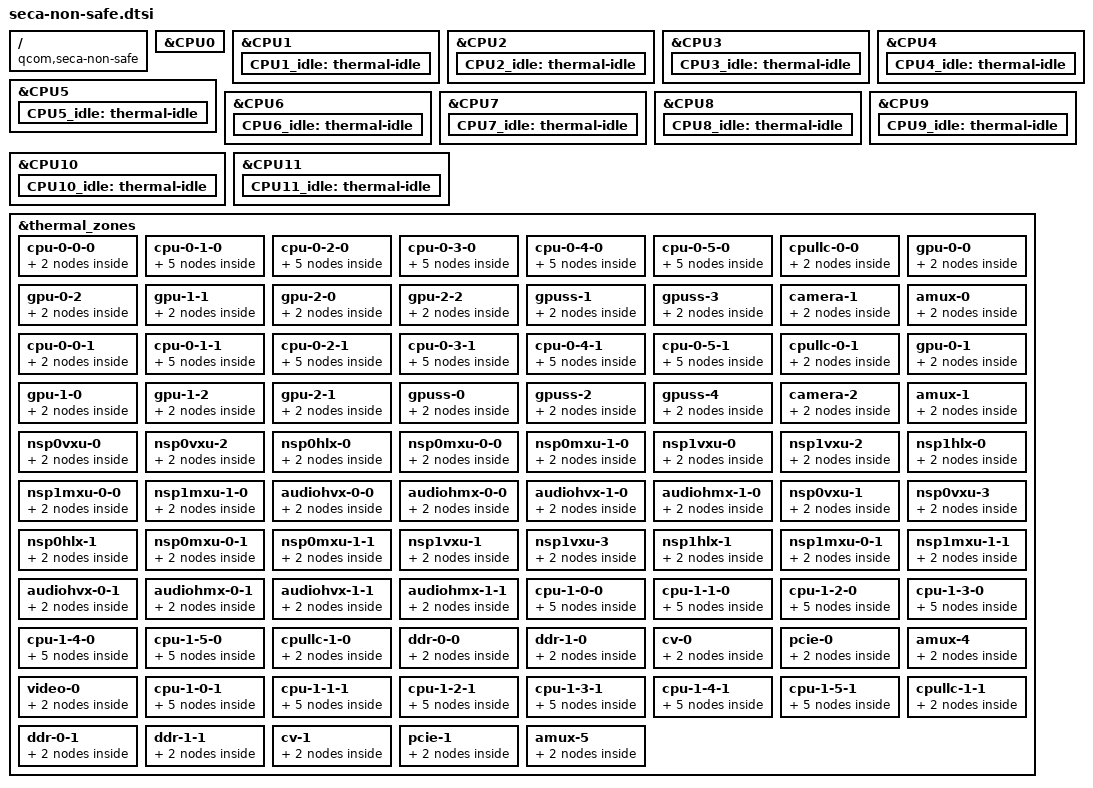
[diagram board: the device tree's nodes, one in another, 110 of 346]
// SPDX-License-Identifier: BSD-3-Clause
/*
 * Copyright (c) Qualcomm Technologies, Inc. and/or its subsidiaries.
 */

/ {
	compatible = "qcom,seca-non-safe","qcom,non-safe";
};

#include <dt-bindings/thermal/thermal.h>

&CPU0 {
	#cooling-cells = <2>;
};

&CPU1 {
	#cooling-cells = <2>;
	CPU1_idle: thermal-idle {
		#cooling-cells = <2>;
		duration-us = <800000>;
		exit-latency-us = <10000>;
	};
};

&CPU2 {
	#cooling-cells = <2>;
	CPU2_idle: thermal-idle {
		#cooling-cells = <2>;
		duration-us = <800000>;
		exit-latency-us = <10000>;
	};
};

&CPU3 {
	#cooling-cells = <2>;
	CPU3_idle: thermal-idle {
		#cooling-cells = <2>;
		duration-us = <800000>;
		exit-latency-us = <10000>;
	};
};

&CPU4 {
	#cooling-cells = <2>;
	CPU4_idle: thermal-idle {
		#cooling-cells = <2>;
		duration-us = <800000>;
		exit-latency-us = <10000>;
	};
};

&CPU5 {
	#cooling-cells = <2>;
	CPU5_idle: thermal-idle {
		#cooling-cells = <2>;
		duration-us = <800000>;
		exit-latency-us = <10000>;
	};
};

&CPU6 {
	#cooling-cells = <2>;
	CPU6_idle: thermal-idle {
		#cooling-cells = <2>;
		duration-us = <800000>;
		exit-latency-us = <10000>;
	};
};

&CPU7 {
	#cooling-cells = <2>;
	CPU7_idle: thermal-idle {
		#cooling-cells = <2>;
		duration-us = <800000>;
		exit-latency-us = <10000>;
	};
};

&CPU8 {
	#cooling-cells = <2>;
	CPU8_idle: thermal-idle {
		#cooling-cells = <2>;
		duration-us = <800000>;
		exit-latency-us = <10000>;
	};
};

&CPU9 {
	#cooling-cells = <2>;
	CPU9_idle: thermal-idle {
		#cooling-cells = <2>;
		duration-us = <800000>;
		exit-latency-us = <10000>;
	};
};

&CPU10 {
	#cooling-cells = <2>;
	CPU10_idle: thermal-idle {
		#cooling-cells = <2>;
		duration-us = <800000>;
		exit-latency-us = <10000>;
	};
};

&CPU11 {
	#cooling-cells = <2>;
	CPU11_idle: thermal-idle {
		#cooling-cells = <2>;
		duration-us = <800000>;
		exit-latency-us = <10000>;
	};
};


&thermal_zones {
	cpu-0-0-0 {
		trips {
			trip-point2 {
				temperature = <115000>;
				hysteresis = <3000>;
				type = "critical";
			};
		};
	};

	cpu-0-1-0 {
		trips {
			trip-point2 {
				temperature = <115000>;
				hysteresis = <3000>;
				type = "critical";
			};

			cpu1_alert0: trip-point1 {
				temperature = <114000>;
				hysteresis = <3000>;
			};
		};

		cooling-maps {
			map0 {
				trip = <&cpu1_alert0>;
				cooling-device = <&CPU1_idle 100 100>;
			};
		};
	};

	cpu-0-2-0 {
		trips {
			trip-point2 {
				temperature = <115000>;
				hysteresis = <3000>;
				type = "critical";
			};

			cpu2_alert0: trip-point1 {
				temperature = <114000>;
				hysteresis = <3000>;
			};
		};

		cooling-maps {
			map0 {
				trip = <&cpu2_alert0>;
				cooling-device = <&CPU2_idle 100 100>;
			};
		};
	};

	cpu-0-3-0 {
		trips {
			trip-point2 {
				temperature = <115000>;
				hysteresis = <3000>;
				type = "critical";
			};

			cpu3_alert0: trip-point1 {
				temperature = <114000>;
				hysteresis = <3000>;
			};
		};

		cooling-maps {
			map0 {
				trip = <&cpu3_alert0>;
				cooling-device = <&CPU3_idle 100 100>;
			};
		};
	};

	cpu-0-4-0 {
		trips {
			trip-point2 {
				temperature = <115000>;
				hysteresis = <3000>;
				type = "critical";
			};

			cpu4_alert0: trip-point1 {
				temperature = <114000>;
				hysteresis = <3000>;
			};
		};

		cooling-maps {
			map0 {
				trip = <&cpu4_alert0>;
				cooling-device = <&CPU4_idle 100 100>;
			};
		};
	};

	cpu-0-5-0 {
		trips {
			trip-point2 {
				temperature = <115000>;
				hysteresis = <3000>;
				type = "critical";
			};

			cpu5_alert0: trip-point1 {
				temperature = <114000>;
				hysteresis = <3000>;
			};
		};

		cooling-maps {
			map0 {
				trip = <&cpu5_alert0>;
				cooling-device = <&CPU5_idle 100 100>;
			};
		};
	};

	cpullc-0-0 {
		trips {
			trip-point2 {
				temperature = <115000>;
				hysteresis = <3000>;
				type = "critical";
			};
		};
	};

	gpu-0-0 {
		trips {
			trip-point2 {
				temperature = <115000>;
				hysteresis = <3000>;
				type = "critical";
			};
		};
	};

	gpu-0-2 {
		trips {
			trip-point2 {
				temperature = <115000>;
				hysteresis = <3000>;
				type = "critical";
			};
		};
	};

	gpu-1-1 {
		trips {
			trip-point2 {
				temperature = <115000>;
				hysteresis = <3000>;
				type = "critical";
			};
		};
	};

	gpu-2-0 {
		trips {
			trip-point2 {
				temperature = <115000>;
				hysteresis = <3000>;
				type = "critical";
			};
		};
	};

	gpu-2-2 {
		trips {
			trip-point2 {
				temperature = <115000>;
				hysteresis = <3000>;
				type = "critical";
			};
		};
	};

	gpuss-1 {
		trips {
			trip-point2 {
				temperature = <115000>;
				hysteresis = <3000>;
				type = "critical";
			};
		};
	};

	gpuss-3 {
		trips {
			trip-point2 {
				temperature = <115000>;
				hysteresis = <3000>;
				type = "critical";
			};
		};
	};

	camera-1 {
		trips {
			trip-point2 {
				temperature = <115000>;
				hysteresis = <3000>;
				type = "critical";
			};
		};
	};

	amux-0 {
		trips {
			trip-point2 {
				temperature = <115000>;
				hysteresis = <3000>;
				type = "critical";
			};
		};
	};

	cpu-0-0-1 {
		trips {
			trip-point2 {
				temperature = <115000>;
				hysteresis = <3000>;
				type = "critical";
			};
		};
	};

	cpu-0-1-1 {
		trips {
			trip-point2 {
				temperature = <115000>;
				hysteresis = <3000>;
				type = "critical";
			};

			cpu1_alert1: trip-point1 {
				temperature = <114000>;
				hysteresis = <3000>;
			};
		};

		cooling-maps {
			map0 {
				trip = <&cpu1_alert1>;
				cooling-device = <&CPU1_idle 100 100>;
			};
		};
	};

	cpu-0-2-1 {
		trips {
			trip-point2 {
				temperature = <115000>;
				hysteresis = <3000>;
				type = "critical";
			};

			cpu2_alert1: trip-point1 {
				temperature = <114000>;
				hysteresis = <3000>;
			};
		};

		cooling-maps {
			map0 {
				trip = <&cpu2_alert1>;
				cooling-device = <&CPU2_idle 100 100>;
			};
		};
	};

	cpu-0-3-1 {
		trips {
			trip-point2 {
				temperature = <115000>;
				hysteresis = <3000>;
				type = "critical";
			};

			cpu3_alert1: trip-point1 {
				temperature = <114000>;
				hysteresis = <3000>;
			};
		};

		cooling-maps {
			map0 {
				trip = <&cpu3_alert1>;
				cooling-device = <&CPU3_idle 100 100>;
			};
		};
	};

	cpu-0-4-1 {
		trips {
			trip-point2 {
				temperature = <115000>;
				hysteresis = <3000>;
				type = "critical";
			};

			cpu4_alert1: trip-point1 {
				temperature = <114000>;
				hysteresis = <3000>;
			};
		};

		cooling-maps {
			map0 {
				trip = <&cpu4_alert1>;
				cooling-device = <&CPU4_idle 100 100>;
			};
		};
	};

	cpu-0-5-1 {
		trips {
			trip-point2 {
				temperature = <115000>;
				hysteresis = <3000>;
				type = "critical";
			};

			cpu5_alert1: trip-point1 {
				temperature = <114000>;
				hysteresis = <3000>;
			};
		};

		cooling-maps {
			map0 {
				trip = <&cpu5_alert1>;
				cooling-device = <&CPU5_idle 100 100>;
			};
		};
	};

	cpullc-0-1 {
		trips {
			trip-point2 {
				temperature = <115000>;
				hysteresis = <3000>;
				type = "critical";
			};
		};
	};

	gpu-0-1 {
		trips {
			trip-point2 {
				temperature = <115000>;
				hysteresis = <3000>;
				type = "critical";
			};
		};
	};

	gpu-1-0 {
		trips {
			trip-point2 {
				temperature = <115000>;
				hysteresis = <3000>;
				type = "critical";
			};
		};
	};

	gpu-1-2 {
		trips {
			trip-point2 {
				temperature = <115000>;
				hysteresis = <3000>;
				type = "critical";
			};
		};
	};

	gpu-2-1 {
		trips {
			trip-point2 {
				temperature = <115000>;
				hysteresis = <3000>;
				type = "critical";
			};
		};
	};

	gpuss-0 {
		trips {
			trip-point2 {
				temperature = <115000>;
				hysteresis = <3000>;
				type = "critical";
			};
		};
	};

	gpuss-2 {
		trips {
			trip-point2 {
				temperature = <115000>;
				hysteresis = <3000>;
				type = "critical";
			};
		};
	};

	gpuss-4 {
		trips {
			trip-point2 {
				temperature = <115000>;
				hysteresis = <3000>;
				type = "critical";
			};
		};
	};

	camera-2 {
		trips {
			trip-point2 {
				temperature = <115000>;
				hysteresis = <3000>;
				type = "critical";
			};
		};
	};

	amux-1 {
		trips {
			trip-point2 {
				temperature = <115000>;
				hysteresis = <3000>;
				type = "critical";
			};
		};
	};

	nsp0vxu-0 {
		trips {
			trip-point2 {
				temperature = <115000>;
				hysteresis = <3000>;
				type = "critical";
			};
		};
	};

	nsp0vxu-2 {
		trips {
			trip-point2 {
				temperature = <115000>;
				hysteresis = <3000>;
				type = "critical";
			};
		};
	};

	nsp0hlx-0 {
		trips {
			trip-point2 {
				temperature = <115000>;
				hysteresis = <3000>;
				type = "critical";
			};
		};
	};

	nsp0mxu-0-0 {
		trips {
			trip-point2 {
				temperature = <115000>;
				hysteresis = <3000>;
				type = "critical";
			};
		};
	};

	nsp0mxu-1-0 {
		trips {
			trip-point2 {
				temperature = <115000>;
				hysteresis = <3000>;
				type = "critical";
			};
		};
	};

	nsp1vxu-0 {
		trips {
			trip-point2 {
				temperature = <115000>;
				hysteresis = <3000>;
				type = "critical";
			};
		};
	};

	nsp1vxu-2 {
		trips {
			trip-point2 {
				temperature = <115000>;
				hysteresis = <3000>;
				type = "critical";
			};
		};
	};

	nsp1hlx-0 {
		trips {
			trip-point2 {
				temperature = <115000>;
				hysteresis = <3000>;
				type = "critical";
			};
		};
	};

	nsp1mxu-0-0 {
		trips {
			trip-point2 {
				temperature = <115000>;
				hysteresis = <3000>;
				type = "critical";
			};
		};
	};

	nsp1mxu-1-0 {
		trips {
			trip-point2 {
				temperature = <115000>;
				hysteresis = <3000>;
				type = "critical";
			};
		};
	};

	audiohvx-0-0 {
		trips {
			trip-point2 {
				temperature = <115000>;
				hysteresis = <3000>;
				type = "critical";
			};
		};
	};

	audiohmx-0-0 {
		trips {
			trip-point2 {
				temperature = <115000>;
				hysteresis = <3000>;
				type = "critical";
			};
		};
	};

	audiohvx-1-0 {
		trips {
			trip-point2 {
				temperature = <115000>;
				hysteresis = <3000>;
				type = "critical";
			};
		};
	};

	audiohmx-1-0 {
		trips {
			trip-point2 {
				temperature = <115000>;
				hysteresis = <3000>;
				type = "critical";
			};
		};
	};

	nsp0vxu-1 {
		trips {
			trip-point2 {
				temperature = <115000>;
				hysteresis = <3000>;
				type = "critical";
			};
		};
	};

	nsp0vxu-3 {
		trips {
			trip-point2 {
				temperature = <115000>;
				hysteresis = <3000>;
				type = "critical";
			};
		};
	};

	nsp0hlx-1 {
		trips {
			trip-point2 {
				temperature = <115000>;
				hysteresis = <3000>;
				type = "critical";
			};
		};
	};

	nsp0mxu-0-1 {
		trips {
			trip-point2 {
				temperature = <115000>;
				hysteresis = <3000>;
				type = "critical";
			};
		};
	};

	nsp0mxu-1-1 {
		trips {
			trip-point2 {
				temperature = <115000>;
				hysteresis = <3000>;
				type = "critical";
			};
		};
	};

	nsp1vxu-1 {
		trips {
			trip-point2 {
				temperature = <115000>;
				hysteresis = <3000>;
				type = "critical";
			};
		};
	};

	nsp1vxu-3 {
		trips {
			trip-point2 {
				temperature = <115000>;
				hysteresis = <3000>;
				type = "critical";
			};
		};
	};

	nsp1hlx-1 {
		trips {
			trip-point2 {
				temperature = <115000>;
				hysteresis = <3000>;
				type = "critical";
			};
		};
	};

	nsp1mxu-0-1 {
		trips {
			trip-point2 {
				temperature = <115000>;
				hysteresis = <3000>;
				type = "critical";
			};
		};
	};

	nsp1mxu-1-1 {
		trips {
			trip-point2 {
				temperature = <115000>;
				hysteresis = <3000>;
				type = "critical";
			};
		};
	};

	audiohvx-0-1 {
		trips {
			trip-point2 {
				temperature = <115000>;
				hysteresis = <3000>;
				type = "critical";
			};
		};
	};

	audiohmx-0-1 {
		trips {
			trip-point2 {
				temperature = <115000>;
				hysteresis = <3000>;
				type = "critical";
			};
		};
	};

	audiohvx-1-1 {
		trips {
			trip-point2 {
				temperature = <115000>;
				hysteresis = <3000>;
				type = "critical";
			};
		};
	};

	audiohmx-1-1 {
		trips {
			trip-point2 {
				temperature = <115000>;
				hysteresis = <3000>;
				type = "critical";
			};
		};
	};

	cpu-1-0-0 {
		trips {
			trip-point2 {
				temperature = <115000>;
				hysteresis = <3000>;
				type = "critical";
			};

			cpu6_alert0: trip-point1 {
				temperature = <114000>;
				hysteresis = <3000>;
			};
		};

		cooling-maps {
			map0 {
				trip = <&cpu6_alert0>;
				cooling-device = <&CPU6_idle 100 100>;
			};
		};
	};

	cpu-1-1-0 {
		trips {
			trip-point2 {
				temperature = <115000>;
				hysteresis = <3000>;
				type = "critical";
			};

			cpu7_alert0: trip-point1 {
				temperature = <114000>;
				hysteresis = <3000>;
			};
		};

		cooling-maps {
			map0 {
				trip = <&cpu7_alert0>;
				cooling-device = <&CPU7_idle 100 100>;
			};
		};
	};

	cpu-1-2-0 {
		trips {
			trip-point2 {
				temperature = <115000>;
				hysteresis = <3000>;
				type = "critical";
			};

			cpu8_alert0: trip-point1 {
				temperature = <114000>;
				hysteresis = <3000>;
			};
		};

		cooling-maps {
			map0 {
				trip = <&cpu8_alert0>;
				cooling-device = <&CPU8_idle 100 100>;
			};
		};
	};

	cpu-1-3-0 {
		trips {
			trip-point2 {
				temperature = <115000>;
				hysteresis = <3000>;
				type = "critical";
			};

			cpu9_alert0: trip-point1 {
				temperature = <114000>;
				hysteresis = <3000>;
			};
		};

		cooling-maps {
			map0 {
				trip = <&cpu9_alert0>;
				cooling-device = <&CPU9_idle 100 100>;
			};
		};
	};

	cpu-1-4-0 {
		trips {
			trip-point2 {
				temperature = <115000>;
				hysteresis = <3000>;
				type = "critical";
			};

			cpu10_alert0: trip-point1 {
				temperature = <114000>;
				hysteresis = <3000>;
			};
		};

		cooling-maps {
			map0 {
				trip = <&cpu10_alert0>;
				cooling-device = <&CPU10_idle 100 100>;
			};
		};
	};

	cpu-1-5-0 {
		trips {
			trip-point2 {
				temperature = <115000>;
				hysteresis = <3000>;
				type = "critical";
			};

			cpu11_alert0: trip-point1 {
				temperature = <114000>;
				hysteresis = <3000>;
			};
		};

		cooling-maps {
			map0 {
				trip = <&cpu11_alert0>;
				cooling-device = <&CPU11_idle 100 100>;
			};
		};
	};

	cpullc-1-0 {
		trips {
			trip-point2 {
				temperature = <115000>;
				hysteresis = <3000>;
				type = "critical";
			};
		};
	};

	ddr-0-0 {
		trips {
			trip-point2 {
				temperature = <115000>;
				hysteresis = <3000>;
				type = "critical";
			};
		};
	};

	ddr-1-0 {
		trips {
			trip-point2 {
				temperature = <115000>;
				hysteresis = <3000>;
				type = "critical";
			};
		};
	};

	cv-0 {
		trips {
			trip-point2 {
				temperature = <115000>;
				hysteresis = <3000>;
				type = "critical";
			};
		};
	};

	pcie-0 {
		trips {
			trip-point2 {
				temperature = <115000>;
				hysteresis = <3000>;
				type = "critical";
			};
		};
	};

	amux-4 {
		trips {
			trip-point2 {
				temperature = <115000>;
				hysteresis = <3000>;
				type = "critical";
			};
		};
	};

	video-0 {
		trips {
			trip-point2 {
				temperature = <115000>;
				hysteresis = <3000>;
				type = "critical";
			};
		};
	};

	cpu-1-0-1 {
		trips {
			trip-point2 {
				temperature = <115000>;
				hysteresis = <3000>;
				type = "critical";
			};

			cpu6_alert1: trip-point1 {
				temperature = <114000>;
				hysteresis = <3000>;

			};
		};

		cooling-maps {
			map0 {
				trip = <&cpu6_alert1>;
				cooling-device = <&CPU6_idle 100 100>;
			};
		};
	};

	cpu-1-1-1 {
		trips {
			trip-point2 {
				temperature = <115000>;
				hysteresis = <3000>;
				type = "critical";
			};

			cpu7_alert1: trip-point1 {
				temperature = <114000>;
				hysteresis = <3000>;
			};
		};

		cooling-maps {
			map0 {
				trip = <&cpu7_alert1>;
				cooling-device = <&CPU7_idle 100 100>;
			};
		};
	};

	cpu-1-2-1 {
		trips {
			trip-point2 {
				temperature = <115000>;
				hysteresis = <3000>;
				type = "critical";
			};

			cpu8_alert1: trip-point1 {
				temperature = <114000>;
				hysteresis = <3000>;
			};
		};

		cooling-maps {
			map0 {
				trip = <&cpu8_alert1>;
				cooling-device = <&CPU8_idle 100 100>;
			};
		};
	};

	cpu-1-3-1 {
		trips {
			trip-point2 {
				temperature = <115000>;
				hysteresis = <3000>;
				type = "critical";
			};

			cpu9_alert1: trip-point1 {
				temperature = <114000>;
				hysteresis = <3000>;
			};
		};

		cooling-maps {
			map0 {
				trip = <&cpu9_alert1>;
				cooling-device = <&CPU9_idle 100 100>;
			};
		};
	};

	cpu-1-4-1 {
		trips {
			trip-point2 {
				temperature = <115000>;
				hysteresis = <3000>;
				type = "critical";
			};

			cpu10_alert1: trip-point1 {
				temperature = <114000>;
				hysteresis = <3000>;
			};
		};

		cooling-maps {
			map0 {
				trip = <&cpu10_alert1>;
				cooling-device = <&CPU10_idle 100 100>;
			};
		};
	};

	cpu-1-5-1 {
		trips {
			trip-point2 {
				temperature = <115000>;
				hysteresis = <3000>;
				type = "critical";
			};

			cpu11_alert1: trip-point1 {
				temperature = <114000>;
				hysteresis = <3000>;
			};
		};

		cooling-maps {
			map0 {
				trip = <&cpu11_alert1>;
				cooling-device = <&CPU11_idle 100 100>;
			};
		};
	};

	cpullc-1-1 {
		trips {
			trip-point2 {
				temperature = <115000>;
				hysteresis = <3000>;
				type = "critical";
			};
		};
	};

	ddr-0-1 {
		trips {
			trip-point2 {
				temperature = <115000>;
				hysteresis = <3000>;
				type = "critical";
			};
		};
	};

	ddr-1-1 {
		trips {
			trip-point2 {
				temperature = <115000>;
				hysteresis = <3000>;
				type = "critical";
			};
		};
	};

	cv-1 {
		trips {
			trip-point2 {
				temperature = <115000>;
				hysteresis = <3000>;
				type = "critical";
			};
		};
	};

	pcie-1 {
		trips {
			trip-point2 {
				temperature = <115000>;
				hysteresis = <3000>;
				type = "critical";
			};
		};
	};

	amux-5 {
		trips {
			trip-point2 {
				temperature = <115000>;
				hysteresis = <3000>;
				type = "critical";
			};
		};
	};
};
